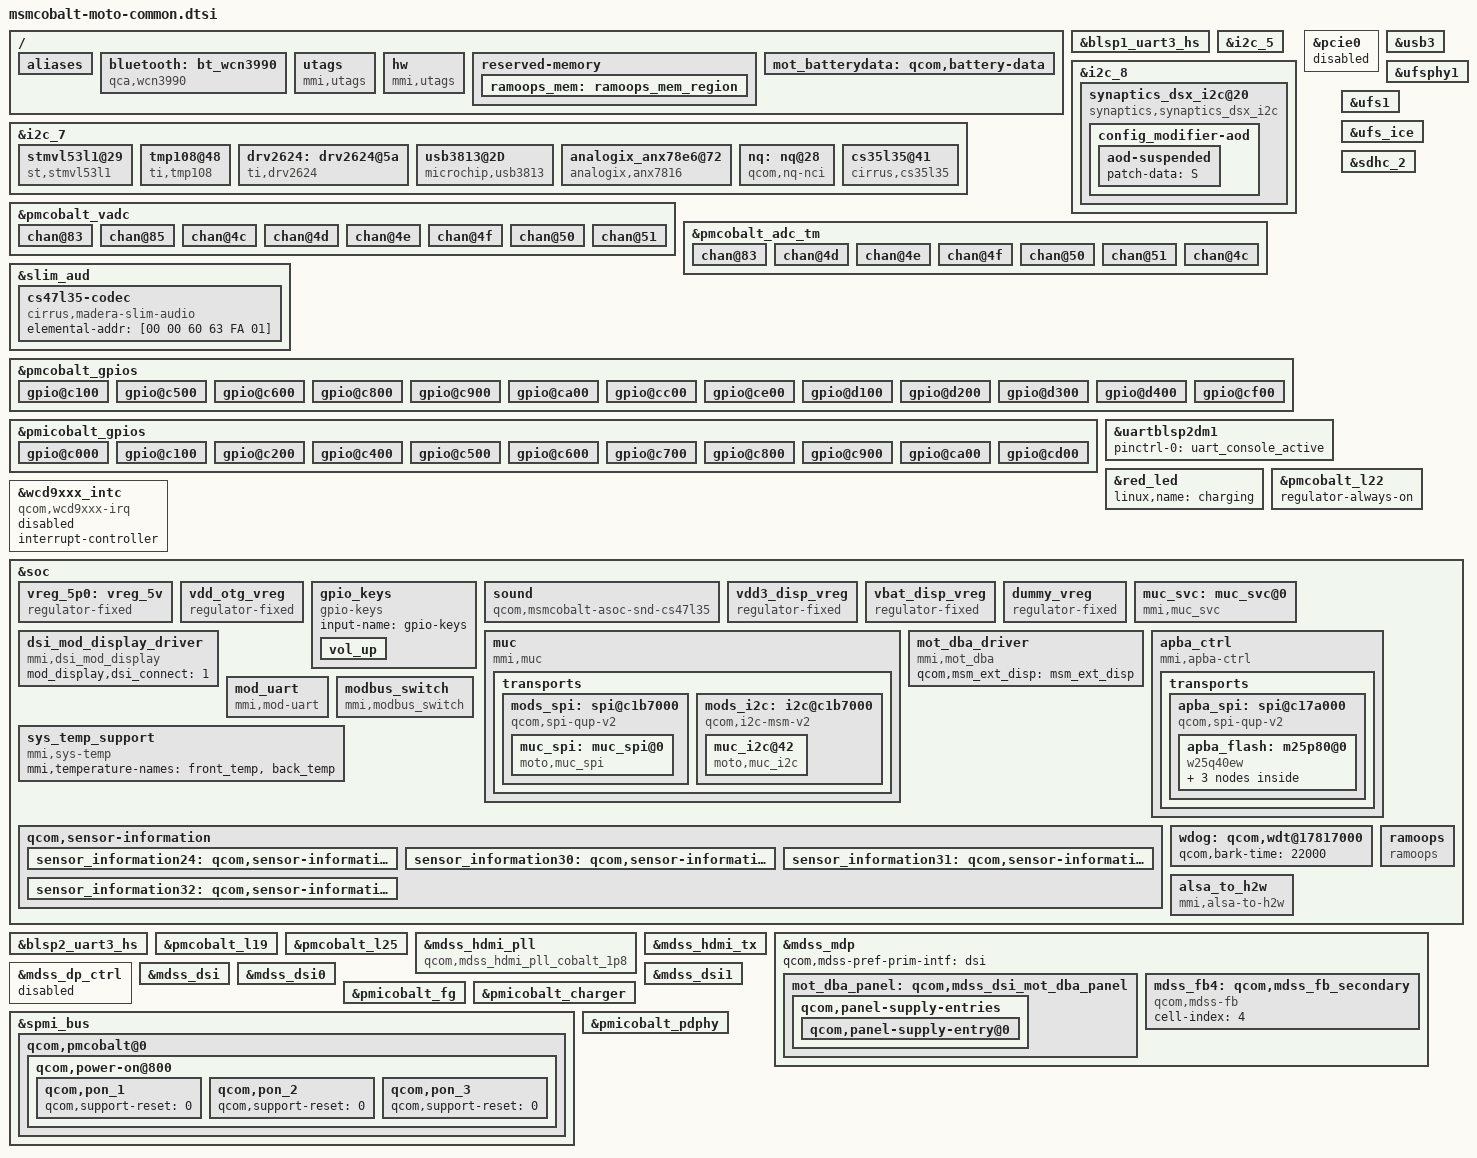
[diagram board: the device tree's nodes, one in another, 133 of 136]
/* Copyright (c) 2016, Motorola Mobility Inc. All rights reserved.
 *
 * This program is free software; you can redistribute it and/or modify
 * it under the terms of the GNU General Public License version 2 and
 * only version 2 as published by the Free Software Foundation.
 *
 * This program is distributed in the hope that it will be useful,
 * but WITHOUT ANY WARRANTY; without even the implied warranty of
 * MERCHANTABILITY or FITNESS FOR A PARTICULAR PURPOSE.  See the
 * GNU General Public License for more details.
 */


#include "msmcobalt-pinctrl.dtsi"
#include "msmcobalt-moto-pinctrl.dtsi"
#include "msmcobalt-mdss.dtsi"
#include "msmcobalt-moto-fps.dtsi"
#include "msm8998-camera-sensor-mot.dtsi"
#include "carrier-channel-ids.dtsi"
#include "dsi-panel-mot-dummy-qhd-video.dtsi"
#include "dsi-panel-mot-smd-546-QHD-g-cmd.dtsi"
#include "dsi-panel-mot-smd-546-QHD-p-cmd.dtsi"
#include <moto-mem-reserve.h>

/ {
	aliases {
		uart6 = &blsp2_uart3_hs;
		i2c1 = &mods_i2c;
		uart0 = &blsp1_uart3_hs;
	};

	bluetooth: bt_wcn3990 {
		compatible = "qca,wcn3990";
		qca,bt-vdd-io-supply = <&pmcobalt_s3>;
		qca,bt-vdd-xtal-supply = <&pmcobalt_s5>;
		qca,bt-vdd-core-supply = <&pmcobalt_l7_pin_ctrl>;
		qca,bt-vdd-pa-supply = <&pmcobalt_l17_pin_ctrl>;
		qca,bt-vdd-ldo-supply = <&pmcobalt_l25_pin_ctrl>;
		qca,bt-chip-pwd-supply = <&pmicobalt_bob_pin1>;

		qca,bt-vdd-io-voltage-level = <1352000 1352000>;
		qca,bt-vdd-xtal-voltage-level = <2040000 2040000>;
		qca,bt-vdd-core-voltage-level = <1800000 1800000>;
		qca,bt-vdd-pa-voltage-level = <1304000 1304000>;
		qca,bt-vdd-ldo-voltage-level = <3312000 3312000>;
		qca,bt-chip-pwd-voltage-level = <3600000 3600000>;

		qca,bt-vdd-io-current-level = <1>; /* LPM/PFM */
		qca,bt-vdd-xtal-current-level = <1>; /* LPM/PFM */
		qca,bt-vdd-core-current-level = <0>; /* LPM/PFM */
		qca,bt-vdd-pa-current-level = <0>; /* LPM/PFM */
		qca,bt-vdd-ldo-current-level = <0>; /* LPM/PFM */
	};

	utags {
		compatible = "mmi,utags";
		mmi,main-utags = "/dev/block/bootdevice/by-name/utags";
		mmi,backup-utags = "/dev/block/bootdevice/by-name/utagsBackup";
	};

	hw {
		compatible = "mmi,utags";
		mmi,dir-name = "hw";
		mmi,main-utags = "/dev/block/bootdevice/by-name/hw";
	};

	reserved-memory {
		ramoops_mem: ramoops_mem_region {
			no-map;
			reg = <0x0 0xaf000000 0x0 0x80000>;
			label = "ramoops_mem";
		};
		/* tzlog_bck_region and wdog_cpuctx_region not yet supported. */
	};
};

&blsp1_uart3_hs {
	status = "ok";
};

&i2c_5 {
	/delete-node/ synaptics@20;
};

&i2c_7 {
	status = "ok";

	stmvl53l1@29 {
		/* Enable once the matching driver is ported completely */
		status = "ok";
		compatible = "st,stmvl53l1";
		reg = <0x29>;
		/* L22 is always on for now */
		/* vdd-supply = <&pmcobalt_l22>; */
		gpios = <&pmcobalt_gpios 15 0>, <&tlmm 79 0>;
		qcom,gpio-reset = <0>;
		qcom,gpio-req-tbl-num = <0 1>;
		qcom,gpio-req-tbl-flags = <0 1>;
		qcom,gpio-req-tbl-label ="TOF_XSHUTDOWN","TOF_INT";
		pinctrl-names = "laser_default", "laser_suspend";
		pinctrl-0 = <&laser_active >;
		pinctrl-1 = <&laser_suspend >;
		st,sensorthreshold = <60 65>;
		st,xtalkval = <19>;
	};

	tmp108@48 {
		compatible = "ti,tmp108";
		reg = <0x48>;
		interrupt-parent = <&tlmm>;
		gpios = <&tlmm 80 0>;

		pinctrl-names = "default";
		pinctrl-0 = <&tmp108_irq_default>;
		label = "quiet_tmp108";
	};

	drv2624: drv2624@5a {
		compatible = "ti,drv2624";
		reg = <0x5A>;
		/* voltage = *_voltage x 22 mV */
		/* 2V for now */
		ti,rated_voltage = /bits/ 8 <0x5B>;
		ti,overdrive_voltage = /bits/ 8 <0x5B>;
		/* LRA period = lra_freq x 24.39 us */
		/* 200 Hz for now */
		ti,lra_freq = /bits/ 8 <0xCD>;
		ti,lra_drive;
		ti,auto_cal;
		ti,nrst-gpio = <&pmicobalt_gpios 9 0>;   /* EN_GPIO */
	};

	usb3813@2D {
		status = "ok";
                compatible = "microchip,usb3813";
                reg = <0x2D>;
                gpios = <&pmicobalt_gpios 5 0x0>,   /* HUB_RESET_EN */
                        <&pmicobalt_gpios 1 0x1>;    /* HUB_INT_EN */
                gpio-labels = "gpio_hub_reset_n",
                        "gpio_hub_int_n";
                clock-names = "hub_clk";
		/* msm-clocks-cobalt.h PM8998 LN_BB_CLK2 -> LNBB_CLK2 */
                clocks = <&clock_gcc clk_ln_bb_clk2>;
                enable-usbhost;
                vdd-hsic-supply = <&pmicobalt_bob>;
        };

	analogix_anx78e6@72 {
		compatible = "analogix,anx7816";
		status = "ok";
		reg = <0x72>;
		clock-names = "dp_bridge_mclk";
		clocks = <&clock_gcc clk_ln_bb_clk2>;
		interrupt-parent = <&tlmm>;
		/* cbl-det-gpio is interrupt pin */
		interrupts = <124 (IRQ_TYPE_EDGE_RISING | IRQ_TYPE_EDGE_FALLING)>;
		analogix,reset-gpio = <&tlmm 133 0x00>;
/* TODO: Don't know if we need this in our configuration
		analogix,irq-gpio = <&msm_gpio 53 0x00>; */
		analogix,cbl-det-gpio = <&tlmm 124 0x00>;
		analogix,p-dwn-gpio = <&tlmm 96 0x0>;   /* chip_pd */
		analogix,vdd_33-supply = <&pmcobalt_l25>;
		analogix,vdd_18-supply = <&pmcobalt_s4>;
		analogix,vdd_10-supply = <&pmcobalt_l3>;
		analogix,i2c-pull-up = <1>;
		qcom,hdmi-tx-map = <&mdss_hdmi_tx>;

		pinctrl-names = "anx_default", "anx_sleep";
		pinctrl-0 = <&anx_rst_active>;
		pinctrl-1 = <&anx_rst_suspend>;
	};

	nq:nq@28 {		/* NFC PN553 */
		compatible = "qcom,nq-nci";
		reg = <0x28>;
		interrupt-parent = <&tlmm>;
		interrupts = <92 0>;
		interrupt-names = "nfc_irq";
		qcom,nq-irq = <&tlmm 92 0x00>;
		qcom,nq-ven = <&tlmm 12 0x00>;
		qcom,nq-firm = <&tlmm 93 0x00>;

		pinctrl-names = "default";
		pinctrl-0 = <&nfc_irq_default &nfc_ven_default &nfc_firm_default>;

		/* Clock */
		qcom,clk-src = "BBCLK3";
		qcom,nq-clkreq = <&pmcobalt_gpios 21 0x00>;
		clocks = <&clock_gcc clk_ln_bb_clk3_pin>;
		clock-names = "ref_clk";
	};

	cs35l35@41 {
		compatible = "cirrus,cs35l35";
		reg = <0x41>;
		reset-gpios = <&tlmm 97 0>;
		irq-gpios = <&tlmm 127 0>;
		interrupt-parent = <&tlmm>;
		VA-supply = <&dummy_vreg>;
		VP-supply = <&dummy_vreg>;

		pinctrl-name = "default";
		pinctrl-0 = <&cs35l35_reset_default &cs35l35_irq_default>;
	};
};

&i2c_8 {
	status = "ok";

	synaptics_dsx_i2c@20 {
		compatible = "synaptics,synaptics_dsx_i2c";
		reg = <0x20>;
		interrupt-parent = <&tlmm>;
		interrupts = <115 0>;
		gpios = <&tlmm 115 0>, /* IRQ */
			<&tlmm 39 0>; /* RESET */
		touch_vdd-supply = <&pmcobalt_l28>;
		synaptics,gpio-config;
		pinctrl-names = "default", "active";
		pinctrl-0 = <&touch_reset_active &touch_int_suspend>;
		pinctrl-1 = <&touch_reset_active &touch_int_active>;
		config_modifier-names = "aod";
		config_modifier-aod {
			aod-suspended {
				/* Power->sleep; */
				patch-data = "S";
			};
		};
	};
};

&pcie0 {
	status = "disabled";
};

&usb3{
	mmi,ext-typec-switch;
	qcom,ssusb-compliance;
};

&pmcobalt_vadc {
	chan@83 {
		label = "vph_pwr";
		reg = <0x83>;
		qcom,decimation = <2>;
		qcom,pre-div-channel-scaling = <1>;
		qcom,calibration-type = "absolute";
		qcom,scale-function = <0>;
		qcom,hw-settle-time = <0>;
		qcom,fast-avg-setup = <0>;
	};

	chan@85 {
		label = "vcoin";
		reg = <0x85>;
		qcom,decimation = <2>;
		qcom,pre-div-channel-scaling = <1>;
		qcom,calibration-type = "absolute";
		qcom,scale-function = <0>;
		qcom,hw-settle-time = <0>;
		qcom,fast-avg-setup = <0>;
	};

	chan@4c {
		label = "xo_therm";
		reg = <0x4c>;
		qcom,decimation = <2>;
		qcom,pre-div-channel-scaling = <0>;
		qcom,calibration-type = "ratiometric";
		qcom,scale-function = <4>;
		qcom,hw-settle-time = <2>;
		qcom,fast-avg-setup = <0>;
	};

	chan@4d {
		label = "msm_therm";
		reg = <0x4d>;
		qcom,decimation = <2>;
		qcom,pre-div-channel-scaling = <0>;
		qcom,calibration-type = "ratiometric";
		qcom,scale-function = <2>;
		qcom,hw-settle-time = <2>;
		qcom,fast-avg-setup = <0>;
	};

	chan@4e {
		label = "ufs_therm";
		reg = <0x4e>;
		qcom,decimation = <2>;
		qcom,pre-div-channel-scaling = <0>;
		qcom,calibration-type = "ratiometric";
		qcom,scale-function = <2>;
		qcom,hw-settle-time = <2>;
		qcom,fast-avg-setup = <0>;
	};

	chan@4f {
		label = "pa_therm0";
		reg = <0x4f>;
		qcom,decimation = <2>;
		qcom,pre-div-channel-scaling = <0>;
		qcom,calibration-type = "ratiometric";
		qcom,scale-function = <2>;
		qcom,hw-settle-time = <2>;
		qcom,fast-avg-setup = <0>;
	};

	chan@50 {
		label = "pa_therm1";
		reg = <0x50>;
		qcom,decimation = <2>;
		qcom,pre-div-channel-scaling = <0>;
		qcom,calibration-type = "ratiometric";
		qcom,scale-function = <2>;
		qcom,hw-settle-time = <2>;
		qcom,fast-avg-setup = <0>;
	};

	chan@51 {
		label = "quiet_therm";
		reg = <0x51>;
		qcom,decimation = <2>;
		qcom,pre-div-channel-scaling = <0>;
		qcom,calibration-type = "ratiometric";
		qcom,scale-function = <2>;
		qcom,hw-settle-time = <2>;
		qcom,fast-avg-setup = <0>;
	};
};

&pmcobalt_adc_tm {
	chan@83 {
		label = "vph_pwr";
		reg = <0x83>;
		qcom,pre-div-channel-scaling = <1>;
		qcom,calibration-type = "absolute";
		qcom,scale-function = <0>;
		qcom,hw-settle-time = <0>;
		qcom,btm-channel-number = <0x60>;
	};

	chan@4d {
		label = "msm_therm";
		reg = <0x4d>;
		qcom,pre-div-channel-scaling = <0>;
		qcom,calibration-type = "ratiometric";
		qcom,scale-function = <2>;
		qcom,hw-settle-time = <2>;
		qcom,btm-channel-number = <0x68>;
		qcom,thermal-node;
	};

	chan@4e {
		label = "ufs_therm";
		reg = <0x4e>;
		qcom,pre-div-channel-scaling = <0>;
		qcom,calibration-type = "ratiometric";
		qcom,scale-function = <2>;
		qcom,hw-settle-time = <2>;
		qcom,btm-channel-number = <0x70>;
		qcom,thermal-node;
	};

	chan@4f {
		label = "pa_therm0";
		reg = <0x4f>;
		qcom,pre-div-channel-scaling = <0>;
		qcom,calibration-type = "ratiometric";
		qcom,scale-function = <2>;
		qcom,hw-settle-time = <2>;
		qcom,btm-channel-number = <0x78>;
		qcom,thermal-node;
	};

	chan@50 {
		label = "pa_therm1";
		reg = <0x50>;
		qcom,pre-div-channel-scaling = <0>;
		qcom,calibration-type = "ratiometric";
		qcom,scale-function = <2>;
		qcom,hw-settle-time = <2>;
		qcom,btm-channel-number = <0x80>;
		qcom,thermal-node;
	};

	chan@51 {
		label = "quiet_therm";
		reg = <0x51>;
		qcom,pre-div-channel-scaling = <0>;
		qcom,calibration-type = "ratiometric";
		qcom,scale-function = <2>;
		qcom,hw-settle-time = <2>;
		qcom,btm-channel-number = <0x88>;
		qcom,thermal-node;
	};

	chan@4c {
		label = "xo_therm";
		reg = <0x4c>;
		qcom,pre-div-channel-scaling = <0>;
		qcom,calibration-type = "ratiometric";
		qcom,scale-function = <4>;
		qcom,hw-settle-time = <2>;
		qcom,btm-channel-number = <0x90>;
		qcom,thermal-node;
	};
};

&slim_aud {
	/delete-node/ tasha_codec;
	/delete-node/ tavil_codec;

	cs47l35-codec {
		compatible = "cirrus,madera-slim-audio";
		elemental-addr = [00 00 60 63 FA 01];
	};
};

&pmcobalt_gpios {
	gpio@c100 { /* PM8998_GPIO2 MOD_MPHY_SEL0 */
		qcom,mode = <1>;         /* QPNP_PIN_MODE_DIG_OUT */
		qcom,output-type = <0>;  /* QPNP_PIN_OUT_BUF_CMOS */
		qcom,vin-sel = <0>;      /* QPNP_PIN_VIN0 */
		qcom,src-sel = <0>;      /* QPNP_PIN_SEL_FUNC_CONSTANT */
		qcom,out-strength = <1>; /* QPNP_PIN_OUT_STRENGTH_LOW */
		qcom,invert = <0>;	 /* Invert */
		qcom,master-en = <1>;
		status = "okay";
	};

	gpio@c500 { /* PM8998_GPIO6 VOL_UP */
		qcom,mode = <0>;         /* QPNP_PIN_MODE_DIG_IN */
		qcom,output-type = <0>;  /* QPNP_PIN_OUT_BUF_CMOS */
		qcom,vin-sel = <0>;      /* QPNP_PIN_VIN0 */
		qcom,src-sel = <0>;      /* QPNP_PIN_SEL_FUNC_CONSTANT */
		qcom,out-strength = <1>; /* QPNP_PIN_OUT_STRENGTH_LOW */
		qcom,pull = <5>;	 /* QPNP_PIN_PULL_NO */
		qcom,master-en = <1>;
		status = "okay";
	};

	gpio@c600 { /* PM8998_GPIO7 DISP_V2_EN */
		qcom,mode = <1>;         /* QPNP_PIN_MODE_DIG_OUT */
		qcom,output-type = <0>;  /* QPNP_PIN_OUT_BUF_CMOS */
		qcom,vin-sel = <0>;      /* QPNP_PIN_VIN0 */
		qcom,src-sel = <0>;      /* QPNP_PIN_SEL_FUNC_CONSTANT */
		qcom,out-strength = <1>; /* QPNP_PIN_OUT_STRENGTH_LOW */
		qcom,pull = <0>;	 /* QPNP_PIN_GPIO_PULL_UP_30 */
		qcom,master-en = <1>;
		status = "okay";
	};

	gpio@c800 { /* PM8998_GPIO9 APBA_1P1_EN */
		qcom,mode = <1>;         /* QPNP_PIN_MODE_DIG_OUT */
		qcom,pull = <5>;         /* QPNP_PIN_PULL_NO */
		qcom,output-type = <0>;  /* QPNP_PIN_OUT_BUF_CMOS */
		qcom,vin-sel = <0>;      /* QPNP_PIN_VIN0 */
		qcom,src-sel = <0>;      /* QPNP_PIN_SEL_FUNC_CONSTANT */
		qcom,out-strength = <1>; /* QPNP_PIN_OUT_STRENGTH_LOW */
		qcom,master-en = <1>;
		status = "okay";
	};

	gpio@c900 { /* PM8998_GPIO10 SPK_5V_BOOST_EN */
		qcom,mode = <1>;         /* QPNP_PIN_MODE_DIG_OUT */
		qcom,pull = <5>;         /* QPNP_PIN_PULL_NO */
		qcom,output-type = <0>;  /* QPNP_PIN_OUT_BUF_CMOS */
		qcom,vin-sel = <0>;      /* QPNP_PIN_VIN0 */
		qcom,src-sel = <0>;      /* QPNP_PIN_SEL_FUNC_CONSTANT */
		qcom,out-strength = <1>; /* QPNP_PIN_OUT_STRENGTH_LOW */
		qcom,master-en = <1>;
		status = "okay";
	};

	gpio@ca00 { /* PM8998_GPIO11 - TGL_RST/FACT_EN */
		qcom,mode = <1>;	/* Digital output */
		qcom,pull = <5>;	/* No Pull */
		qcom,vin-sel = <0>;	/* 1.8 */
		qcom,src-sel = <0>;	/* GPIO */
		qcom,out-strength = <1>;/* QPNP_PIN_OUT_STRENGTH_LOW */
		qcom,pull = <5>;	/* QPNP_PIN_PULL_NO */
		qcom,master-en = <1>;	/* Enable GPIO */
		status = "okay";
	};

	gpio@cc00 { /* PM8998_GPIO13 DIV_CLK1 */
		qcom,mode = <1>;         /* QPNP_PIN_MODE_DIG_OUT */
		qcom,output-type = <0>;  /* QPNP_PIN_OUT_BUF_CMOS */
		qcom,vin-sel = <0>;      /* QPNP_PIN_VIN0 */
		qcom,src-sel = <2>;      /* QPNP_PIN_LV_MV_SEL_FUNC_1 */
		qcom,out-strength = <1>; /* QPNP_PIN_OUT_STRENGTH_LOW */
		qcom,pull = <5>;	 /* QPNP_PIN_PULL_NO */
		qcom,master-en = <1>;
		status = "okay";
	};

	gpio@ce00 { /* PM8998_GPIO15 FOCUS_XSHUT */
		qcom,mode = <1>;         /* QPNP_PIN_MODE_DIG_OUT */
		qcom,output-type = <0>;  /* QPNP_PIN_OUT_BUF_CMOS */
		qcom,vin-sel = <0>;      /* QPNP_PIN_VIN0 */
		qcom,src-sel = <0>;      /* QPNP_PIN_SEL_FUNC_CONSTANT */
		qcom,out-strength = <1>; /* QPNP_PIN_OUT_STRENGTH_LOW */
		qcom,invert = <0>;	 /* Invert */
		qcom,master-en = <1>;
		status = "ok";
	};

	gpio@d100 { /* PM8998_GPIO18 NFC_POWER_ON */
		qcom,mode = <1>;         /* QPNP_PIN_MODE_DIG_OUT */
		qcom,output-type = <0>;  /* QPNP_PIN_OUT_BUF_CMOS */
		qcom,vin-sel = <0>;      /* QPNP_PIN_VIN0 */
		qcom,src-sel = <0>;      /* QPNP_PIN_SEL_FUNC_CONSTANT */
		qcom,out-strength = <1>; /* QPNP_PIN_OUT_STRENGTH_LOW */
		qcom,invert = <0>;	 /* Invert */
		qcom,master-en = <1>;
		status = "ok";
	};

	gpio@d200 { /* PM8998_GPIO19 SDC_DET_N */
		qcom,mode = <0>;         /* QPNP_PIN_MODE_DIG_IN */
		qcom,output-type = <0>;  /* QPNP_PIN_OUT_BUF_CMOS */
		qcom,vin-sel = <1>;      /* QPNP_PIN_VIN1 */
		qcom,src-sel = <0>;      /* QPNP_PIN_SEL_FUNC_CONSTANT */
		qcom,out-strength = <1>; /* QPNP_PIN_OUT_STRENGTH_LOW */
		qcom,pull = <0>;	 /* QPNP_PIN_GPIO_PULL_UP_30 */
		qcom,invert = <0>;	 /* Invert */
		qcom,master-en = <1>;
		status = "ok";
	};

	gpio@d300 { /* PM8998_GPIO20 USB_AUD_DET_N */
		qcom,mode = <1>;         /* QPNP_PIN_MODE_DIG_OUT */
		qcom,output-type = <0>;  /* QPNP_PIN_OUT_BUF_CMOS */
		qcom,vin-sel = <1>;      /* QPNP_PIN_VIN1 */
		qcom,src-sel = <0>;      /* QPNP_PIN_SEL_FUNC_CONSTANT */
		qcom,out-strength = <1>; /* QPNP_PIN_OUT_STRENGTH_LOW */
		qcom,pull = <5>;	 /* QPNP_PIN_PULL_NO */
		qcom,invert = <1>;	 /* Invert */
		qcom,master-en = <1>;
		status = "ok";
	};

	gpio@d400 { /* PM8998_GPIO21 NFC_CLK_REQ */
		qcom,mode = <1>;         /* QPNP_PIN_MODE_DIG_OUT */
		qcom,output-type = <0>;  /* QPNP_PIN_OUT_BUF_CMOS */
		qcom,vin-sel = <1>;      /* QPNP_PIN_VIN1 for this pin this is the low voltage */
		qcom,src-sel = <0>;      /* QPNP_PIN_SEL_FUNC_CONSTANT */
		qcom,out-strength = <1>; /* QPNP_PIN_OUT_STRENGTH_LOW */
		qcom,invert = <0>;	 /* Invert */
		qcom,master-en = <1>;
		status = "ok";
	};

	gpio@cf00 { /* PM8998_GPIO16 SLEEP_CLK4 */
		qcom,mode = <1>;         /* QPNP_PIN_MODE_DIG_OUT */
		qcom,output-type = <0>;  /* QPNP_PIN_OUT_BUF_CMOS */
		qcom,vin-sel = <0>;      /* QPNP_PIN_VIN0 */
		qcom,src-sel = <2>;      /* QPNP_PIN_LV_MV_SEL_FUNC_1 */
		qcom,out-strength = <1>; /* QPNP_PIN_OUT_STRENGTH_LOW */
		qcom,pull = <5>;	 /* QPNP_PIN_PULL_NO */
		qcom,master-en = <1>;
		status = "okay";
	};

};

&pmicobalt_gpios {

	/* ATTENTION!!! PLEASE USE 1.8 V as vin-sel unless high voltage is required */
	/* PMI8998 GPIOs 1, 3, 4, 6, 7, 8, 11 and 13 have VIN0 3.6 V and VIN1 1.8 V */

	gpio@c000 { /* PMI8998_GPIO1 HSIC_INT_N */
		qcom,mode = <0>;         /* QPNP_PIN_MODE_DIG_IN */
		qcom,output-type = <0>;  /* QPNP_PIN_OUT_BUF_CMOS */
		qcom,vin-sel = <1>;      /* QPNP_PIN_VIN1 */
		qcom,src-sel = <0>;      /* QPNP_PIN_SEL_FUNC_CONSTANT */
		qcom,out-strength = <1>; /* QPNP_PIN_OUT_STRENGTH_LOW */
		qcom,master-en = <1>;
		status = "okay";
	};

	gpio@c100 { /* PMI8998_GPIO2 USB_OTG_FAULT_N */
		qcom,mode = <0>;         /* QPNP_PIN_MODE_DIG_IN */
		qcom,output-type = <0>;  /* QPNP_PIN_OUT_BUF_CMOS */
		qcom,vin-sel = <0>;      /* QPNP_PIN_VIN0 */
		qcom,src-sel = <0>;      /* QPNP_PIN_SEL_FUNC_CONSTANT */
		qcom,out-strength = <1>; /* QPNP_PIN_OUT_STRENGTH_LOW */
		qcom,master-en = <1>;
		status = "okay";
	};

	gpio@c200 { /* PMI8998_GPIO3 USB_OTG_EN */
		qcom,mode = <1>;         /* QPNP_PIN_MODE_DIG_OUT */
		qcom,output-type = <0>;  /* QPNP_PIN_OUT_BUF_CMOS */
		qcom,vin-sel = <1>;      /* QPNP_PIN_VIN1 */
		qcom,src-sel = <0>;      /* QPNP_PIN_SEL_FUNC_CONSTANT */
		qcom,out-strength = <1>; /* QPNP_PIN_OUT_STRENGTH_LOW */
		qcom,master-en = <1>;
		status = "okay";
	};


	gpio@c400 { /* PMI8998_GPIO5 HSIC_RESET_N */
		qcom,mode = <1>;         /* QPNP_PIN_MODE_DIG_OUT */
		qcom,output-type = <0>;  /* QPNP_PIN_OUT_BUF_CMOS */
		qcom,vin-sel = <0>;      /* QPNP_PIN_VIN0 */
		qcom,src-sel = <0>;      /* QPNP_PIN_SEL_FUNC_CONSTANT */
		qcom,out-strength = <1>; /* QPNP_PIN_OUT_STRENGTH_LOW */
		qcom,master-en = <1>;
		status = "okay";
	};

	gpio@c500 { /* PMI8998_GPIO6 RF_BOOST_BYP_EN TPS61280A */
		qcom,mode = <1>;         /* QPNP_PIN_MODE_DIG_OUT */
		qcom,output-type = <0>;  /* QPNP_PIN_OUT_BUF_CMOS */
		qcom,vin-sel = <1>;      /* QPNP_PIN_VIN1 */
		qcom,src-sel = <0>;      /* QPNP_PIN_SEL_FUNC_CONSTANT */
		qcom,out-strength = <1>; /* QPNP_PIN_OUT_STRENGTH_LOW */
		qcom,invert = <1>;	 /* Invert */
		qcom,master-en = <1>;
		status = "okay";
	};

	gpio@c600 { /* PMI8998_GPIO7 RF_BOOST_BYP_MODE TPS61280A */
		qcom,mode = <1>;         /* QPNP_PIN_MODE_DIG_OUT */
		qcom,output-type = <0>;  /* QPNP_PIN_OUT_BUF_CMOS */
		qcom,vin-sel = <0>;      /* QPNP_PIN_VIN0 */
		qcom,src-sel = <0>;      /* QPNP_PIN_SEL_FUNC_CONSTANT */
		qcom,out-strength = <1>; /* QPNP_PIN_OUT_STRENGTH_LOW */
		qcom,invert = <1>;	 /* Invert */
		qcom,master-en = <1>;
		status = "okay";
	};

	gpio@c700 { /* PMI8998_GPIO8 TX_GTR_THRES */
		qcom,mode = <1>;         /* QPNP_PIN_MODE_DIG_OUT */
		qcom,output-type = <0>;  /* QPNP_PIN_OUT_BUF_CMOS */
		qcom,vin-sel = <1>;      /* QPNP_PIN_VIN1 */
		qcom,src-sel = <0>;      /* QPNP_PIN_SEL_FUNC_CONSTANT */
		qcom,out-strength = <1>; /* QPNP_PIN_OUT_STRENGTH_LOW */
		qcom,master-en = <1>;
		status = "okay";
	};

	gpio@c800 { /* PMI8998_GPIO9 VIB_RST_N */
		qcom,mode = <1>;         /* QPNP_PIN_MODE_DIG_OUT */
		qcom,output-type = <0>;  /* QPNP_PIN_OUT_BUF_CMOS */
		qcom,vin-sel = <0>;      /* QPNP_PIN_VIN0 */
		qcom,src-sel = <0>;      /* QPNP_PIN_SEL_FUNC_CONSTANT */
		qcom,out-strength = <1>; /* QPNP_PIN_OUT_STRENGTH_LOW */
		qcom,master-en = <1>;
		status = "okay";
	};

	gpio@c900 { /* PMI8998_GPIO10 MOD_BP_OC_FAULT_N */
		qcom,mode = <0>;         /* QPNP_PIN_MODE_DIG_IN */
		qcom,output-type = <0>;  /* QPNP_PIN_OUT_BUF_CMOS */
		qcom,vin-sel = <0>;      /* QPNP_PIN_VIN0 */
		qcom,src-sel = <0>;      /* QPNP_PIN_SEL_FUNC_CONSTANT */
		qcom,out-strength = <1>; /* QPNP_PIN_OUT_STRENGTH_LOW */
		qcom,master-en = <1>;
		status = "okay";
	};

	gpio@ca00 { /* PMI8998_GPIO11 MOD_BPLUS_LIM */
		qcom,mode = <1>;         /* QPNP_PIN_MODE_DIG_OUT */
		qcom,output-type = <0>;  /* QPNP_PIN_OUT_BUF_CMOS */
		qcom,vin-sel = <1>;      /* QPNP_PIN_VIN1 */
		qcom,src-sel = <0>;      /* QPNP_PIN_SEL_FUNC_CONSTANT */
		qcom,out-strength = <1>; /* QPNP_PIN_OUT_STRENGTH_LOW */
		qcom,master-en = <1>;
		status = "okay";
	};

	gpio@cd00 { /* PMI8998_GPIO14 CC_ALERT */
		qcom,mode = <0>;         /* QPNP_PIN_MODE_DIG_IN */
		qcom,output-type = <0>;  /* QPNP_PIN_OUT_BUF_CMOS */
		qcom,vin-sel = <0>;      /* QPNP_PIN_VIN0 */
		qcom,src-sel = <0>;      /* QPNP_PIN_SEL_FUNC_CONSTANT */
		qcom,out-strength = <1>; /* QPNP_PIN_OUT_STRENGTH_LOW */
		qcom,master-en = <1>;
		status = "okay";
	};
};

&uartblsp2dm1 {
	status = "ok";
	pinctrl-names = "default";
	pinctrl-0 = <&uart_console_active>;
};

&ufsphy1 {
	vdda-phy-supply = <&pmcobalt_l1>;
	vdda-pll-supply = <&pmcobalt_l2>;
	vddp-ref-clk-supply = <&pmcobalt_l26>;
	vdda-phy-max-microamp = <51400>;
	vdda-pll-max-microamp = <14600>;
	vddp-ref-clk-max-microamp = <100>;
	vddp-ref-clk-always-on;
	status = "ok";
};

&ufs1 {
	vdd-hba-supply = <&gdsc_ufs>;
	vdd-hba-fixed-regulator;
	vcc-supply = <&pmcobalt_l20>;
	vccq-supply = <&pmcobalt_l26>;
	vccq2-supply = <&pmcobalt_s4>;
	vcc-max-microamp = <750000>;
	vccq-max-microamp = <560000>;
	vccq2-max-microamp = <750000>;
	status = "ok";
};

&ufs_ice {
	status = "ok";
};

&sdhc_2 {
	vdd-supply = <&pmcobalt_l21>;
	qcom,vdd-voltage-level = <2950000 2960000>;
	qcom,vdd-current-level = <200 800000>;

	vdd-io-supply = <&pmcobalt_l13>;
	qcom,vdd-io-voltage-level = <1808000 2960000>;
	qcom,vdd-io-current-level = <200 22000>;

	pinctrl-names = "active", "sleep";
	pinctrl-0 = <&sdc2_clk_on  &sdc2_cmd_on &sdc2_data_on>;
	pinctrl-1 = <&sdc2_clk_off &sdc2_cmd_off &sdc2_data_off>;

	qcom,clk-rates = <400000 20000000 25000000
				50000000 100000000 200000000>;
	qcom,bus-speed-mode = "SDR12", "SDR25", "SDR50", "DDR50", "SDR104";

	cd-gpios = <&pmcobalt_gpios 19 0x1>;

	status = "ok";
};

&red_led {
	linux,name = "charging";
	/delete-property/ linux,default-trigger;
};

/delete-node/ &green_led;
/delete-node/ &blue_led;

&pmcobalt_l22 {
	regulator-always-on;
};

&wcd9xxx_intc {
	status = "disabled";
	compatible = "qcom,wcd9xxx-irq";
	interrupt-controller;
	#interrupt-cells = <1>;
	interrupt-names = "cdc-int";
};

&soc {
	vreg_5p0: vreg_5v {
		compatible = "regulator-fixed";
		regulator-name = "vreg_5p0";
		gpio = <&pmcobalt_gpios 10 0>;
		enable-active-high;
	};

	vdd_otg_vreg: vdd_otg_vreg {
		compatible = "regulator-fixed";
		regulator-name = "vdd_otg";
		gpio = <&pmicobalt_gpios 3 0>;
		vin-supply = <&vreg_5p0>;
		enable-active-high;
	};

	gpio_keys {
		compatible = "gpio-keys";
		input-name = "gpio-keys";
		status = "okay";

		vol_up {
			label = "volume_up";
			gpios = <&pmcobalt_gpios 6 0x1>;
			linux,input-type = <1>;
			linux,code = <115>;
			gpio-key,wakeup;
			debounce-interval = <15>;
		};
	};

	/delete-node/ sound-9335;
	/delete-node/ sound-tavil;
	sound {
		status = "ok";
		compatible = "qcom,msmcobalt-asoc-snd-cs47l35";
		qcom,model = "msmcobalt-cs47l35-card";
		qcom,ext-disp-audio-rx;

		asoc-platform = <&pcm0>, <&pcm1>, <&pcm2>, <&voip>, <&voice>,
				<&loopback>, <&compress>, <&hostless>,
				<&afe>, <&lsm>, <&routing>, <&cpe>, <&compr>,
				<&pcm_noirq>, <&cs47l35>;
		asoc-platform-names = "msm-pcm-dsp.0", "msm-pcm-dsp.1",
				"msm-pcm-dsp.2", "msm-voip-dsp",
				"msm-pcm-voice", "msm-pcm-loopback",
				"msm-compress-dsp", "msm-pcm-hostless",
				"msm-pcm-afe", "msm-lsm-client",
				"msm-pcm-routing", "msm-cpe-lsm",
				"msm-compr-dsp", "msm-pcm-dsp-noirq",
				"cs47l35-codec";
		asoc-cpu = <&dai_hdmi>, <&dai_dp>,
				<&sb_0_rx>, <&sb_0_tx>, <&sb_1_rx>, <&sb_1_tx>,
				<&sb_2_rx>, <&sb_2_tx>, <&sb_3_rx>, <&sb_3_tx>,
				<&sb_4_rx>, <&sb_4_tx>, <&sb_5_tx>,
				<&afe_pcm_rx>, <&afe_pcm_tx>, <&afe_proxy_rx>,
				<&afe_proxy_tx>, <&incall_record_rx>,
				<&incall_record_tx>, <&incall_music_rx>,
				<&incall_music_2_rx>, <&sb_5_rx>,
				<&usb_audio_rx>, <&usb_audio_tx>, <&sb_6_rx>,
				<&dai_pri_tdm_rx_0>, <&dai_pri_tdm_tx_0>,
				<&dai_sec_tdm_rx_0>, <&dai_sec_tdm_tx_0>,
				<&dai_tert_tdm_rx_0>, <&dai_tert_tdm_tx_0>,
				<&dai_quat_tdm_rx_0>, <&dai_quat_tdm_tx_0>;
		asoc-cpu-names = "msm-dai-q6-hdmi.8",  "msm-dai-q6-dp.24608",
				"msm-dai-q6-dev.16384", "msm-dai-q6-dev.16385",
				"msm-dai-q6-dev.16386", "msm-dai-q6-dev.16387",
				"msm-dai-q6-dev.16388", "msm-dai-q6-dev.16389",
				"msm-dai-q6-dev.16390", "msm-dai-q6-dev.16391",
				"msm-dai-q6-dev.16392", "msm-dai-q6-dev.16393",
				"msm-dai-q6-dev.16395", "msm-dai-q6-dev.224",
				"msm-dai-q6-dev.225", "msm-dai-q6-dev.241",
				"msm-dai-q6-dev.240", "msm-dai-q6-dev.32771",
				"msm-dai-q6-dev.32772", "msm-dai-q6-dev.32773",
				"msm-dai-q6-dev.32770", "msm-dai-q6-dev.16394",
				"msm-dai-q6-dev.28672", "msm-dai-q6-dev.28673",
				"msm-dai-q6-dev.16396",
				"msm-dai-q6-tdm.36864", "msm-dai-q6-tdm.36865",
				"msm-dai-q6-tdm.36880", "msm-dai-q6-tdm.36881",
				"msm-dai-q6-tdm.36896", "msm-dai-q6-tdm.36897",
				"msm-dai-q6-tdm.36912", "msm-dai-q6-tdm.36913";
		asoc-codec = <&stub_codec>, <&ext_disp_audio_codec>;
		asoc-codec-names = "msm-stub-codec.1",
				"msm-ext-disp-audio-codec-rx";
		cs47l35,micbias-routing =
			"IN1AL", "MICBIAS2A",
			"IN2L",  "MICBIAS1B",
			"IN2R",  "MICBIAS2B",
			"IN1BR", "MICBIAS2A";
	};

	vdd3_disp_vreg: vdd3_disp_vreg {
		compatible = "regulator-fixed";
		regulator-name = "vdd3_disp";
		gpio = <&pmcobalt_gpios 7 0>;
		vin-supply = <&pmcobalt_s4>;
		startup-delay-us = <300>;
		enable-active-high;
		regulator-boot-on;
	};

	vbat_disp_vreg: vbat_disp_vreg {
		compatible = "regulator-fixed";
		regulator-name = "vbat_disp";
		gpio = <&tlmm 69 0>;
		startup-delay-us = <300>;
		enable-active-high;
		regulator-boot-on;
	};

	dummy_vreg: dummy_vreg {
		compatible = "regulator-fixed";
		status = "ok";
		regulator-name = "dummy_vreg";
		regulator-always-on;
	};

	muc: muc {
		compatible = "mmi,muc";
		#address-cells = <1>;
		#size-cells = <1>;
		ranges = <0 0 0xffffffff>;

		gpios = <&tlmm 36 1>,            /* gpio_muc_det_n, input */
			<&tlmm 35 0>,            /* gpio_muc_bplus_en, output-low */
			<&tlmm 26 1>,            /* gpio_muc_int_n, input */
			<&tlmm 28 2>,            /* gpio_muc_wake_n, output-high */
			<&tlmm 95 1>,            /* gpio_muc_rdy_n, input */
			<&tlmm 143 0>,           /* gpio_muc_ff, output-low */
			<&tlmm 49 0>,            /* gpio_muc_spi_mosi, output-low */
			<&tlmm 50 1>,            /* gpio_muc_spi_miso, input */
			<&pmicobalt_gpios 11 0>, /* gpio_muc_bplus_iset, cs */
			<0>,                     /* gpio_muc_bplus_discharg, cs */
			<&pmicobalt_gpios 10 1>, /* gpio_muc_bplus_fault_n, input */
			<&tlmm 52 1>;            /* gpio_muc_clk, input */

		mmi,muc-ctrl-gpio-labels = "gpio_muc_det_n",
				"gpio_muc_bplus_en",
				"gpio_muc_int_n",
				"gpio_muc_wake_n",
				"gpio_muc_rdy_n",
				"gpio_muc_ff",
				"gpio_muc_spi_mosi",
				"gpio_muc_spi_miso",
				"gpio_muc_bplus_iset",
				"gpio_muc_bplus_discharg",
				"gpio_muc_bplus_fault_n",
				"gpio_muc_clk";

		mmi,muc-ctrl-det-hysteresis = <200>;
		mmi,muc-ctrl-rm-hysteresis = <5>;
		mmi,muc-ctrl-en-seq =  <1 1 100>;
		mmi,muc-ctrl-dis-seq = <1 0 0>;

		/* v1 FF first, BPLUS second on enable */
		mmi,muc-ctrl-ff-seq-v1 = <5 1 20>, <1 0 100>,
					<1 1 100>, <5 0 20>;

		/* v2 BPLUS first, FF second on enable */
		mmi,muc-ctrl-ff-seq-v2 = <1 1 100>, <5 1 20>,
					<5 0 20>;

		pinctrl-names = "disconnected", "spi_active", "spi_ack", "i2c_active";
		pinctrl-0 = <&muc_attach &muc_det &spi_9_sleep &muc_spi_ctrl>;
		pinctrl-1 = <&muc_attach &muc_det &spi_9_active &muc_spi_ctrl>;
		pinctrl-2 = <&spi_9_mosi_ack &spi_9_miso_ack>;
		pinctrl-3 = <&muc_attach &muc_det &i2c_9_active &muc_spi_ctrl>;

		transports {
			#address-cells = <1>;
			#size-cells = <1>;
			ranges = <0 0 0xffffffff>;

			/* Dummy Place Holder for SPI */
			mods_spi: spi@c1b7000 { };

			/* Dummy Place Holder for I2C */
			mods_i2c: i2c@c1b7000 { };
		};
	};

	muc_svc: muc_svc@0 {
		compatible = "mmi,muc_svc";

		mmi,use-authentication;
		mmi,endo-mask = <0x4755>;
		mmi,default-root-ver = /bits/ 8 <2>;
	};

	dsi_mod_display_driver: dsi_mod_display_driver {
		compatible = "mmi,dsi_mod_display";

		mod_display,dsi_connect = <1>;
	};

	mot_dba_driver: mot_dba_driver {
		compatible = "mmi,mot_dba";

		qcom,msm_ext_disp = <&msm_ext_disp>;
	};

	apba_ctrl {
		compatible = "mmi,apba-ctrl";
		#address-cells = <1>;
		#size-cells = <1>;
		reg = <0 0>;
		ranges = <0 0 0xffffffff>;

		clock-names = "apba_mclk";
		clocks = <&clock_gcc clk_ln_bb_clk2>;

		pinctrl-names = "default", "spi_active";
		pinctrl-0 = <&apba_default &spi_6_sleep>;
		pinctrl-1 = <&apba_default &spi_6_active>;

		gpios = <&pmcobalt_gpios 9 0>,  /* APBA_1P1_EN, output-low */
			<&tlmm 27 0>,           /* APBA_BOOTRET, output-low */
			<&tlmm 38 2>,           /* MOD_MPHY_I2S_SEL, output-high */
			<&tlmm 21 0>,           /* APBA_RESET_N, output-low */
			<&tlmm 37 1>,           /* APBA_INT_N, in */
			<&tlmm 25 0>;           /* APBA_WAKE, output-low */

		mmi,gpio-labels = "gpio_apba_1p1_en",
				"gpio_apba_bootret",
				"gpio_mphy_i2s_sel",
				"gpio_apba_rst_n",
				"gpio_apba_int_n",
				"gpio_apba_wake";

		mmi,int-index = <4>;
		mmi,enable-preclk-seq = <3 0 0>, <5 1 0>, <0 1 0>, <1 0 0>, <2 0 1>;
		mmi,enable-postclk-seq = <3 1 0>;
		mmi,disable-seq = <1 0 0>, <2 1 0>, <3 0 1>, <5 0 0>, <0 0 0>;
		mmi,wake-assert-seq = <5 0 0>;
		mmi,wake-deassert-seq = <5 1 0>;
		mmi,flash-start-seq = <0 1 11>;
		mmi,flash-end-seq = <0 0 0>;
		mmi,apba-unipro-mid = <0x00000126>;
		mmi,apba-unipro-pid = <0x00001001>;
		mmi,apba-ara-vid = <0xfed70128>;
		mmi,apba-ara-pid = <0xfffe0001>;

		transports {
			#address-cells = <1>;
			#size-cells = <1>;
			ranges = <0 0 0xffffffff>;

			/* Dummy Place Holder for SPI */
			apba_spi: spi@c17a000 { };
		};
	};

	mod_uart: mod_uart {
		compatible = "mmi,mod-uart";
		mmi,tty = "ttyHS6";
		mmi,tty_speed = <115200>;
		mmi,intf-id = /bits/ 8 <5>;

		pinctrl-names = "default", "active";
		pinctrl-0 = <&blsp2_uart6_sleep>;
		pinctrl-1 = <&blsp2_uart6_active>;
	};

	modbus_switch {
		compatible = "mmi,modbus_switch";

		gpios = <&pmcobalt_gpios 2 2>,  /* MOD_MPHY_SEL0, output high */
			<&tlmm 98 2>;           /* MOD_MPHY_SEL1, output high */
		mmi,mod-switch-gpio-labels = "MOD_MPHY_SEL0",
						"MOD_MPHY_SEL1";
	};

	sys_temp_support {
		compatible = "mmi,sys-temp";
		mmi,temperature-names = "front_temp",
					"back_temp";
		status = "ok";
	};

	qcom,sensor-information {
		/delete-property/ sensor_information24;
		sensor_information24: qcom,sensor-information-24 {
			qcom,sensor-type =  "adc";
			qcom,sensor-name = "ufs_therm";
		};

		sensor_information30: qcom,sensor-information-30 {
			qcom,sensor-type = "adc";
			qcom,sensor-name = "bms";
			qcom,alias-name  = "batt_therm";
			qcom,scaling-factor = <1000>;
		};
		sensor_information31: qcom,sensor-information-31 {
			qcom,sensor-type = "adc";
			qcom,sensor-name = "front_temp";
			qcom,scaling-factor = <1000>;
		};
		sensor_information32: qcom,sensor-information-32 {
			qcom,sensor-type = "adc";
			qcom,sensor-name = "back_temp";
			qcom,scaling-factor = <1000>;
		};
	};

	wdog: qcom,wdt@17817000 {
		qcom,bark-time = <22000>;
	};

	alsa_to_h2w {
		compatible = "mmi,alsa-to-h2w";
	};

	ramoops {
		compatible = "ramoops";
		status = "ok";

		console-size = <0x0 0x40000>;
		record-size = <0x0 0x3f800>;
		ramoops-annotate-size = <0x0 0x800>;

		memory-region = <&ramoops_mem>;
	};
};

/* Direct Copy of I2C9 from msmcobalt-blsp.dtsi */
&mods_i2c {
	compatible = "qcom,i2c-msm-v2";
	#address-cells = <1>;
	#size-cells = <0>;
	reg-names = "qup_phys_addr";
	reg = <0xC1B7000 0x600>;
	interrupt-names = "qup_irq";
	interrupts = <0 103 0>;
	dmas = <&dma_blsp2 10 64 0x20000020 0x20>,
		<&dma_blsp2 11 32 0x20000020 0x20>;
	dma-names = "tx", "rx";
	qcom,master-id = <84>;
	qcom,clk-freq-out = <400000>;
	qcom,clk-freq-in  = <19200000>;
	clock-names = "iface_clk", "core_clk";
	clocks = <&clock_gcc clk_gcc_blsp2_ahb_clk>,
		 <&clock_gcc clk_gcc_blsp2_qup3_i2c_apps_clk>;
	pinctrl-names = "i2c_active", "i2c_sleep";
	pinctrl-0 = <&i2c_9_active>;
	pinctrl-1 = <&i2c_9_sleep>;
	status = "disabled";
};

/* Overrides of the default I2C configuration for MUC usage */
&mods_i2c {
	compatible = "qcom,i2c-msm-v2", "moto,mod-i2c-transfer";
	status = "okay";

	/delete-property/ pinctrl-0;
	/delete-property/ pinctrl-1;
	/delete-property/ pinctrl-names;

	muc_i2c@42 {
		compatible = "moto,muc_i2c";
		reg = <0x42>;
		interrupt-parent = <&tlmm>;
		interrupts = <26 0>;

		mmi,intf-id = /bits/ 8 <3>;
	};
};

/* Direct Copy of SPI9 from msmcobalt-blsp.dtsi */
&mods_spi {
	compatible = "qcom,spi-qup-v2";
	#address-cells = <1>;
	#size-cells = <0>;
	reg-names = "spi_physical", "spi_bam_physical";
	reg = <0xC1B7000 0x600>,
	      <0xC184000 0x25000>;
	interrupt-names = "spi_irq", "spi_bam_irq";
	interrupts = <0 103 0>, <0 239 0>;
	spi-max-frequency = <50000000>;
	qcom,use-bam;
	qcom,ver-reg-exists;
	qcom,bam-consumer-pipe-index = <10>;
	qcom,bam-producer-pipe-index = <11>;
	qcom,master-id = <84>;
	qcom,use-pinctrl;
	pinctrl-names = "spi_default", "spi_sleep";
	pinctrl-0 = <&spi_9_active>;
	pinctrl-1 = <&spi_9_sleep>;
	clock-names = "iface_clk", "core_clk";
	clocks = <&clock_gcc clk_gcc_blsp2_ahb_clk>,
		 <&clock_gcc clk_gcc_blsp2_qup3_spi_apps_clk>;
	status = "disabled";
};

/* Overrides of the default SPI configuration for MUC usage */
&mods_spi {
	compatible = "qcom,spi-qup-v2", "moto,mod-spi-transfer";
	status = "okay";

	/delete-property/ pinctrl-0;
	/delete-property/ pinctrl-1;
	/delete-property/ pinctrl-names;
	/delete-property/ qcom,use-pinctrl;

	spi-max-frequency = <50000000>;

	qcom,rt-priority;
	qcom,active-only;

	muc_spi: muc_spi@0 {
		compatible = "moto,muc_spi";
		reg = <0>;

		interrupt-parent = <&tlmm>;
		interrupts = <26 0>;
		spi-max-frequency = <4800000>;

		mmi,intf-id = /bits/ 8 <3>;
	};
};

/* Direct Copy of SPI6 from msmcobalt-blsp.dtsi */
&apba_spi {
	compatible = "qcom,spi-qup-v2";
	#address-cells = <1>;
	#size-cells = <0>;
	reg-names = "spi_physical", "spi_bam_physical";
	reg = <0xC17A000 0x600>,
	      <0xC144000 0x25000>;
	interrupt-names = "spi_irq", "spi_bam_irq";
	interrupts = <0 100 0>, <0 238 0>;
	spi-max-frequency = <50000000>;
	qcom,use-bam;
	qcom,ver-reg-exists;
	qcom,bam-consumer-pipe-index = <16>;
	qcom,bam-producer-pipe-index = <17>;
	qcom,master-id = <86>;
	qcom,use-pinctrl;
	pinctrl-names = "spi_default", "spi_sleep";
	pinctrl-0 = <&spi_6_active>;
	pinctrl-1 = <&spi_6_sleep>;
	clock-names = "iface_clk", "core_clk";
	clocks = <&clock_gcc clk_gcc_blsp1_ahb_clk>,
		 <&clock_gcc clk_gcc_blsp1_qup6_spi_apps_clk>;
	status = "disabled";
};

/* Overrides of the default SPI configuration for APBA usage */
&apba_spi {
	compatible = "qcom,spi-qup-v2", "moto,apba-spi-transfer";
	status = "okay";

	spi-max-frequency = <4800000>;

	/delete-property/ pinctrl-0;
	/delete-property/ pinctrl-1;
	/delete-property/ pinctrl-names;
	/delete-property/ qcom,use-pinctrl;

	apba_flash: m25p80@0 {
		compatible = "w25q40ew";
		#address-cells = <1>;
		#size-cells = <1>;
		reg = <0>;
		spi-max-frequency = <4800000>;

		partition@0 {
			label = "apba";
			reg = <0x0 0x40000>;
		};
		partition@1 {
			label = "es2_apbaboot";
			reg = <0x0 0x4000>;
		};
		partition@2 {
			label = "es2_apba";
			reg = <0x4000 0x3C000>;
		};
	};
};

&blsp2_uart3_hs { /* APBA UART */
	status = "ok";

	interrupt-map = <0 &intc 0 0 115 0
		    1 &intc 0 0 239 0
		    2 &tlmm 82 0>;

	/delete-property/ qcom,inject-rx-on-wakeup;
	/delete-property/ qcom,rx-char-to-inject;

	/delete-property/ pinctrl-names;
	/delete-property/ pinctrl-0;
	/delete-property/ pinctrl-1;

	qcom,shared;
};

&pmcobalt_l19 {
	regulator-min-microvolt = <3200000>;
	regulator-max-microvolt = <3200000>;
	qcom,init-voltage = <3200000>;
	regulator-boot-on;
};

&pmcobalt_l25 {
	regulator-min-microvolt = <3312000>;
	regulator-max-microvolt = <3312000>;
	qcom,init-voltage = <3312000>;
};

&mdss_hdmi_pll {
	compatible = "qcom,mdss_hdmi_pll_cobalt_1p8";
};

&mdss_hdmi_tx {
	pinctrl-names = "hdmi_hpd_active", "hdmi_ddc_active", "hdmi_cec_active",
				"hdmi_active", "hdmi_sleep";
	pinctrl-0 = <&mdss_hdmi_5v_active  &mdss_hdmi_hpd_active
			&mdss_hdmi_ddc_suspend &mdss_hdmi_cec_suspend>;
	pinctrl-1 = <&mdss_hdmi_5v_active &mdss_hdmi_hpd_active
			&mdss_hdmi_ddc_active &mdss_hdmi_cec_suspend>;
	pinctrl-2 = <&mdss_hdmi_5v_active &mdss_hdmi_hpd_active
			&mdss_hdmi_cec_active &mdss_hdmi_ddc_suspend>;
	pinctrl-3 = <&mdss_hdmi_5v_active &mdss_hdmi_hpd_active
			&mdss_hdmi_ddc_active &mdss_hdmi_cec_active>;
	pinctrl-4 = <&mdss_hdmi_5v_suspend &mdss_hdmi_hpd_suspend
			&mdss_hdmi_ddc_suspend &mdss_hdmi_cec_suspend>;
};

&mdss_mdp {
	qcom,mdss-pref-prim-intf = "dsi";

	mot_dba_panel: qcom,mdss_dsi_mot_dba_panel{
		#include "dsi-panel-mot-mod-fwvga-video-common.dtsi"
	};

	mdss_fb4: qcom,mdss_fb_secondary {
		cell-index = <4>;
		compatible = "qcom,mdss-fb";
	};
};

&mdss_dp_ctrl {
	status = "disabled";
};

&mdss_dsi {
	hw-config = "dual_dsi";

	qcom,mdss-fb-map-prim = <&mdss_fb0>;
	qcom,mdss-fb-map-sec = <&mdss_fb4>;
};

&mdss_dsi0 {
	qcom,dsi-pref-prim-pan = <&mot_smd_546_QHD_p_cmd_v0>;
	pinctrl-names = "mdss_default", "mdss_sleep";
	pinctrl-0 = <&mdss_dsi_active &mdss_te_active>;
	pinctrl-1 = <&mdss_dsi_suspend &mdss_te_suspend>;
	qcom,platform-reset-gpio = <&tlmm 8 0>;
	qcom,platform-te-gpio = <&tlmm 10 0>;
	qcom,display-id = "primary";

	vbat_disp-supply = <&vbat_disp_vreg>;
	vci_disp-supply = <&pmcobalt_l19>;
	vdd3_disp-supply = <&vdd3_disp_vreg>;

	/delete-property/  qcom,mdss-fb-map;
};

&mdss_dsi1 {
	qcom,dsi-pref-prim-pan = <&mot_dba_panel>;
	apba_cdsi-supply = <&pmcobalt_l26>;
	qcom,pluggable;
	qcom,bridge-index = <0>;

	/delete-property/  qcom,mdss-fb-map;
};

&mot_dba_panel {
	qcom,mdss-dsi-panel-name = "mipi_mot_dba_panel";
	qcom,bridge-name = "mot_dba";
	qcom,mdss-dsi-lane-0-state;
	qcom,mdss-dsi-lane-1-state;
	qcom,mdss-dsi-lane-2-state;
	qcom,mdss-dsi-lane-3-state;

	/* These power supplies are for DBA panel */
	qcom,panel-supply-entries {
		#address-cells = <1>;
		#size-cells = <0>;

		qcom,panel-supply-entry@0 {
			reg = <0>;
			qcom,supply-name = "apba_cdsi";
			qcom,supply-min-voltage = <1100000>;
			qcom,supply-max-voltage = <1300000>;
			qcom,supply-enable-load = <300000>;
			qcom,supply-disable-load = <100>;
			qcom,supply-pre-on-sleep = <0>;
			qcom,supply-post-on-sleep = <1>;
			qcom,supply-pre-off-sleep = <0>;
			qcom,supply-post-off-sleep = <1>;
		};
	};
};


/{
	mot_batterydata: qcom,battery-data {
		qcom,batt-id-range-pct = <100>;
		df-serialnum = "SNN5972";

		#include "batterydata-gv30-lg-pmi8998.dtsi"
	};
};

&pmicobalt_fg {
	qcom,battery-data = <&mot_batterydata>;
	qcom,fg-cutoff-voltage = <3000>;
	qcom,fg-empty-voltage = <2750>;
	qcom,fg-chg-term-current = <170>;
	qcom,fg-sys-term-current = <175>;
	qcom,fg-delta-soc-thr = <1>;
	qcom,fg-recharge-soc-thr = <1>;
	qcom,fg-rsense-sel = <0>;
	qcom,fg-jeita-thresholds = <(-20)>, <0>, <45>, <60>;
};

&pmicobalt_charger {
	gpios = <&tlmm 72 0x0>, /* GPIOF_OUT_INIT_LOW */
		<&tlmm 62 0x1>, /* GPIOF_IN */
		<&pmcobalt_gpios 11 0>; /* TOGL_RST, output-low */
	gpio-names = "eb_vbus_en",
		     "factory_warn",
		     "togl_rst";

	qcom,fcc-max-ua = <3000000>;
	qcom,fv-max-uv = <4400000>;
	qcom,usb-icl-ua = <3000000>;
	qcom,dc-icl-ua = <3000000>;
	qcom,step-soc-thresholds = <50 100 100 100>;
	qcom,step-current-deltas = <0 (-1400000) (-1400000)
					(-1400000) (-1400000)>;
	qcom,thermal-mitigation = <2500>,
				   <1500>,
				   <900>,
				   <600>,
				   <300>;
};

&spmi_bus {
	qcom,pmcobalt@0 {
		qcom,power-on@800 {
			qcom,pon_1 {
				qcom,support-reset = <0>;
			};

			qcom,pon_2 {
				qcom,support-reset = <0>;
			};

			qcom,pon_3 {
				qcom,support-reset = <0>;
			};
		};
	};
};

&pmicobalt_pdphy {
	pinctrl-names = "default";
	pinctrl-0 = <&usb_aud_sw_sel>;

	gpios = <&pmcobalt_gpios 20 0>,  /* USB_AUD_DET_N, output-high */
		<&tlmm 116 0>,           /* USB_AUD_SW_SEL, output-low */
		<&pmicobalt_gpios 2 1>;  /* USB_OTG_FAULT_N, input */

	gpio-labels = "gpio_usb_aud_det_n",
		"gpio_aud_sw_sel",
		"gpio_otg_fault_n";
	vbus-supply = <&vdd_otg_vreg>;
};
